AUTOSAR XML (schema 00046)
package /ComponentTypes
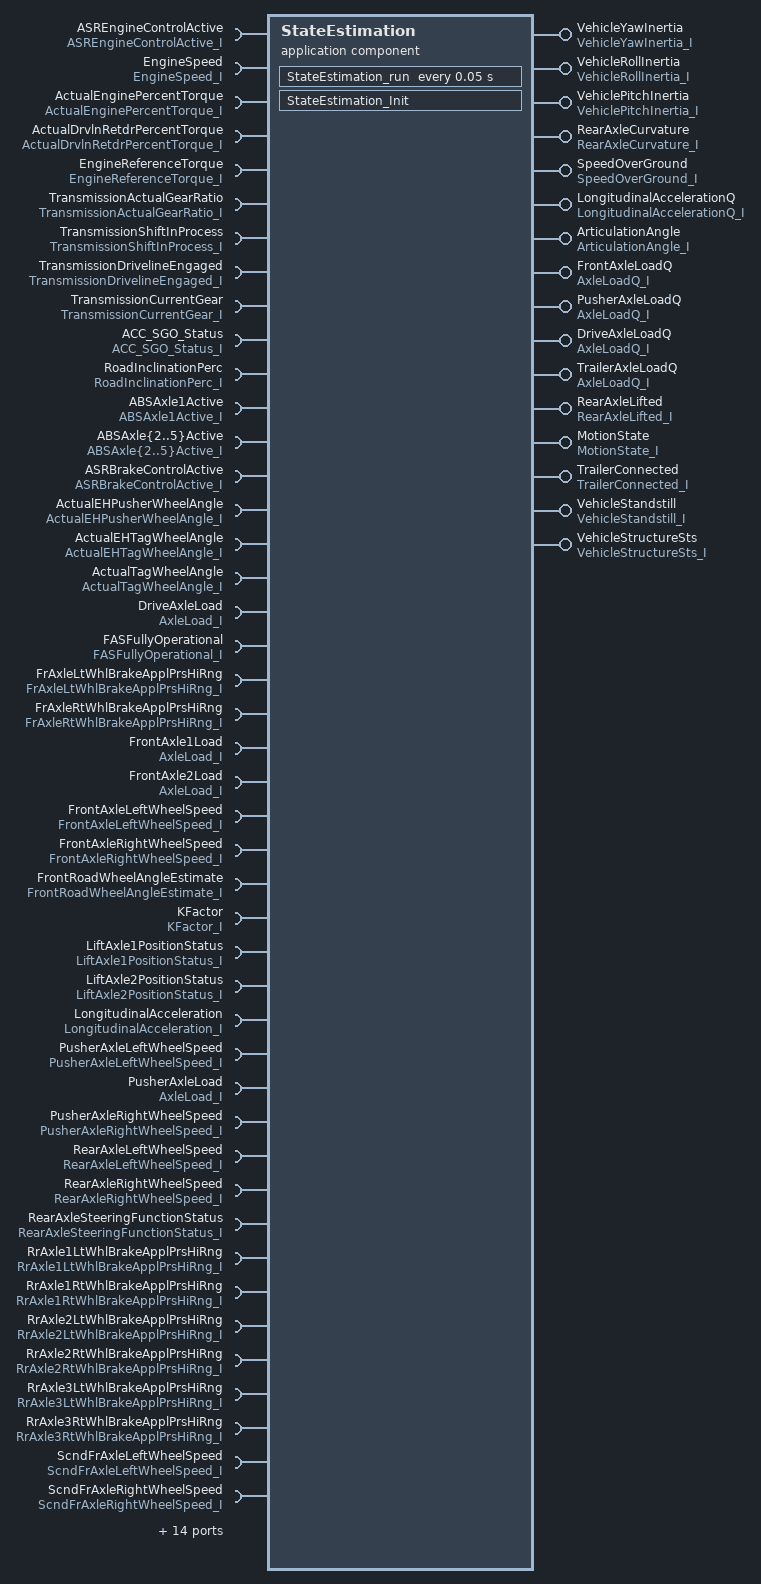
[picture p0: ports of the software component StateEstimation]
  application sw component type StateEstimation
    10 x require port:
      ASREngineControlActive: nonqueued-receiver-com-spec{data-element=ASREngineControlActive, alive-timeout=30, filter=data-filter-type=ALWAYS, init-value=constant-reference=C_ASREngineControlActive_IV}, required-interface=ASREngineControlActive_I
      EngineSpeed: nonqueued-receiver-com-spec{data-element=EngineSpeed, alive-timeout=30, init-value=constant-reference=C_EngineSpeed_IV}, required-interface=EngineSpeed_I
      ActualEnginePercentTorque: nonqueued-receiver-com-spec{data-element=ActualEnginePercentTorque, alive-timeout=30, init-value=constant-reference=C_ActualEnginePercentTorque_IV}, required-interface=ActualEnginePercentTorque_I
      ActualDrvlnRetdrPercentTorque: nonqueued-receiver-com-spec{data-element=ActualDrvlnRetdrPercentTorque, alive-timeout=30, init-value=constant-reference=C_ActualDrvlnRetdrPercentTorque_IV}, required-interface=ActualDrvlnRetdrPercentTorque_I
      EngineReferenceTorque: nonqueued-receiver-com-spec{data-element=EngineReferenceTorque, alive-timeout=30, filter=data-filter-type=ALWAYS, init-value=65535}, required-interface=EngineReferenceTorque_I
      TransmissionActualGearRatio: nonqueued-receiver-com-spec{data-element=TransmissionActualGearRatio, alive-timeout=30, init-value=constant-reference=C_TransmissionActualGearRatio_IV}, required-interface=TransmissionActualGearRatio_I
      TransmissionShiftInProcess: nonqueued-receiver-com-spec{data-element=TransmissionShiftInProcess, alive-timeout=30, init-value=constant-reference=C_TransmissionShiftInProcess_IV}, required-interface=TransmissionShiftInProcess_I
      TransmissionDrivelineEngaged: nonqueued-receiver-com-spec{data-element=TransmissionDrivelineEngaged, alive-timeout=30, init-value=constant-reference=C_TransmissionDrivelineEngaged_IV}, required-interface=TransmissionDrivelineEngaged_I
      TransmissionCurrentGear: nonqueued-receiver-com-spec{data-element=TransmissionCurrentGear, alive-timeout=30, init-value=constant-reference=C_TransmissionCurrentGear_IV}, required-interface=TransmissionCurrentGear_I
      ACC_SGO_Status: nonqueued-receiver-com-spec{data-element=ACC_SGO_Status, alive-timeout=30, init-value=constant-reference=C_ACC_SGO_Status_IV}, required-interface=ACC_SGO_Status_I
    15 x provide port:
      VehicleYawInertia: nonqueued-sender-com-spec{data-element=VehicleYawInertia, init-value=constant-reference=C_VehicleYawInertia_IV}, provided-interface=VehicleYawInertia_I
      VehicleRollInertia: nonqueued-sender-com-spec{data-element=VehicleRollInertia, init-value=constant-reference=C_VehicleRollInertia_IV}, provided-interface=VehicleRollInertia_I
      VehiclePitchInertia: nonqueued-sender-com-spec{data-element=VehiclePitchInertia, init-value=constant-reference=C_VehiclePitchInertia_IV}, provided-interface=VehiclePitchInertia_I
      RearAxleCurvature: nonqueued-sender-com-spec{data-element=RearAxleCurvature, init-value=constant-reference=C_RearAxleCurvature_IV}, provided-interface=RearAxleCurvature_I
      SpeedOverGround: nonqueued-sender-com-spec{data-element=SpeedOverGround, init-value=constant-reference=C_SpeedOverGround_IV}, provided-interface=SpeedOverGround_I
      LongitudinalAccelerationQ: nonqueued-sender-com-spec{data-element=LongitudinalAccelerationQ, init-value=constant-reference=C_LongAccelerationQ_IV}, provided-interface=LongitudinalAccelerationQ_I
      ArticulationAngle: nonqueued-sender-com-spec{data-element=ArticulationAngle, init-value=constant-reference=C_ArticulationAngle_IV}, provided-interface=ArticulationAngle_I
      FrontAxleLoadQ: nonqueued-sender-com-spec{data-element=AxleLoadQ_I, init-value=constant-reference=C_FrontAxleLoadQ_IV}, provided-interface=AxleLoadQ_I
      PusherAxleLoadQ: nonqueued-sender-com-spec{data-element=AxleLoadQ_I, init-value=constant-reference=C_PusherAxleLoadQ_IV}, provided-interface=AxleLoadQ_I
      DriveAxleLoadQ: nonqueued-sender-com-spec{data-element=AxleLoadQ_I, init-value=constant-reference=C_DriveAxleLoadQ_IV}, provided-interface=AxleLoadQ_I
      TrailerAxleLoadQ: nonqueued-sender-com-spec{data-element=AxleLoadQ_I, init-value=constant-reference=C_TrailerAxleLoadQ_IV}, provided-interface=AxleLoadQ_I
      RearAxleLifted: nonqueued-sender-com-spec{data-element=RearAxleLifted_I, init-value=constant-reference=C_RearAxleLifted_IV}, provided-interface=RearAxleLifted_I
      MotionState: nonqueued-sender-com-spec{data-element=MotionState_I, init-value=constant-reference=C_MotionState_IV}, provided-interface=MotionState_I
      TrailerConnected: nonqueued-sender-com-spec{data-element=TrailerConnected, init-value=constant-reference=C_TrailerConnected_IV}, provided-interface=TrailerConnected_I
      VehicleStandstill: nonqueued-sender-com-spec{data-element=VehicleStandstill, init-value=constant-reference=C_VehicleStandstill_IV}, provided-interface=VehicleStandstill_I
    45 x require port:
      RoadInclinationPerc: nonqueued-receiver-com-spec{data-element=RoadInclinationPerc, alive-timeout=30, init-value=0}, required-interface=RoadInclinationPerc_I
      ABSAxle1Active: nonqueued-receiver-com-spec{data-element=ABSAxle1Active, alive-timeout=30, init-value=constant-reference=C_ABSAxle1Active_IV}, required-interface=ABSAxle1Active_I
      ABSAxle{2..5}Active: nonqueued-receiver-com-spec{data-element=ABSAxle{2..5}Active, alive-timeout=30, filter=data-filter-type=ALWAYS, init-value=constant-reference=C_ABSAxle{2..5}Active_IV}, required-interface=ABSAxle{2..5}Active_I
      ASRBrakeControlActive: nonqueued-receiver-com-spec{data-element=ASRBrakeControlActive, alive-timeout=30, init-value=constant-reference=C_ASRBrakeControlActive_IV}, required-interface=ASRBrakeControlActive_I
      ActualEHPusherWheelAngle: nonqueued-receiver-com-spec{data-element=ActuaEHPusherWheelAngle, alive-timeout=30, filter=data-filter-type=ALWAYS, init-value=65535}, required-interface=ActualEHPusherWheelAngle_I
      ActualEHTagWheelAngle: nonqueued-receiver-com-spec{data-element=ActualEHTagWheelAngle, alive-timeout=30, filter=data-filter-type=ALWAYS, init-value=65535}, required-interface=ActualEHTagWheelAngle_I
      ActualTagWheelAngle: nonqueued-receiver-com-spec{data-element=ActualTagWheelAngle, alive-timeout=30, filter=data-filter-type=ALWAYS, init-value=constant-reference=C_ActualTagWheelAngle_IV}, required-interface=ActualTagWheelAngle_I
      DriveAxleLoad: nonqueued-receiver-com-spec{data-element=AxleLoad, alive-timeout=30, filter=data-filter-type=ALWAYS, init-value=constant-reference=C_DriveAxleLoad_IV}, required-interface=AxleLoad_I
      FASFullyOperational: nonqueued-receiver-com-spec{data-element=FASFullyOperational, alive-timeout=30, init-value=constant-reference=C_FASFullyOperational_IV}, required-interface=FASFullyOperational_I
      FrAxleLtWhlBrakeApplPrsHiRng: nonqueued-receiver-com-spec{data-element=FrAxleLtWhlBrakeApplPrsHiRng, alive-timeout=30, init-value=constant-reference=C_FrAxleLtWhlBrakeApplPrsHiRng_IV}, required-interface=FrAxleLtWhlBrakeApplPrsHiRng_I
      FrAxleRtWhlBrakeApplPrsHiRng: nonqueued-receiver-com-spec{data-element=FrAxleRtWhlBrakeApplPrsHiRng, alive-timeout=30, init-value=constant-reference=C_FrAxleRtWhlBrakeApplPrsHiRng_IV}, required-interface=FrAxleRtWhlBrakeApplPrsHiRng_I
      FrontAxle1Load: nonqueued-receiver-com-spec{data-element=AxleLoad, alive-timeout=30, filter=data-filter-type=ALWAYS, init-value=constant-reference=C_FrontAxle1Load_IV}, required-interface=AxleLoad_I
      FrontAxle2Load: nonqueued-receiver-com-spec{data-element=AxleLoad, alive-timeout=30, filter=data-filter-type=ALWAYS, init-value=constant-reference=C_FrontAxle2Load_IV}, required-interface=AxleLoad_I
      FrontAxleLeftWheelSpeed: nonqueued-receiver-com-spec{data-element=FrontAxleLeftWheelSpeed, alive-timeout=30, filter=data-filter-type=ALWAYS, init-value=constant-reference=C_FrontAxleLeftWheelSpeed_IV}, required-interface=FrontAxleLeftWheelSpeed_I
      FrontAxleRightWheelSpeed: nonqueued-receiver-com-spec{data-element=FrontAxleRightWheelSpeed, alive-timeout=30, filter=data-filter-type=ALWAYS, init-value=constant-reference=C_FrontAxleRightWheelSpeed_IV}, required-interface=FrontAxleRightWheelSpeed_I
      FrontRoadWheelAngleEstimate: nonqueued-receiver-com-spec{data-element=FrontRoadWheelAngleEstimate, alive-timeout=30, filter=data-filter-type=ALWAYS, init-value=constant-reference=C_FrontRoadWheelAngleEstimate_IV}, required-interface=FrontRoadWheelAngleEstimate_I
      KFactor: nonqueued-receiver-com-spec{data-element=KFactor, alive-timeout=30, init-value=constant-reference=C_kFactor_IV}, required-interface=KFactor_I
      LiftAxle1PositionStatus: nonqueued-receiver-com-spec{data-element=LiftAxle1PositionStatus, alive-timeout=30, filter=data-filter-type=ALWAYS, init-value=constant-reference=C_LiftAxle1PositionStatus_IV}, required-interface=LiftAxle1PositionStatus_I
      LiftAxle2PositionStatus: nonqueued-receiver-com-spec{data-element=LiftAxle2PositionStatus, alive-timeout=30, filter=data-filter-type=ALWAYS, init-value=constant-reference=C_LiftAxle2PositionStatus_IV}, required-interface=LiftAxle2PositionStatus_I
      LongitudinalAcceleration: nonqueued-receiver-com-spec{data-element=LongitudinalAcceleration, alive-timeout=30, filter=data-filter-type=ALWAYS, init-value=constant-reference=C_LongitudinalAcceleration_IV}, required-interface=LongitudinalAcceleration_I
      PusherAxleLeftWheelSpeed: nonqueued-receiver-com-spec{data-element=PusherAxleLeftWheelSpeed, alive-timeout=30, filter=data-filter-type=ALWAYS, init-value=constant-reference=C_RearAxleLeftWheelSpeed_IV}, required-interface=PusherAxleLeftWheelSpeed_I
      PusherAxleLoad: nonqueued-receiver-com-spec{data-element=AxleLoad, alive-timeout=30, filter=data-filter-type=ALWAYS, init-value=constant-reference=C_PusherAxleLoad_IV}, required-interface=AxleLoad_I
      PusherAxleRightWheelSpeed: nonqueued-receiver-com-spec{data-element=PusherAxleRightWheelSpeed, alive-timeout=30, filter=data-filter-type=ALWAYS, init-value=65535}, required-interface=PusherAxleRightWheelSpeed_I
      RearAxleLeftWheelSpeed: nonqueued-receiver-com-spec{data-element=RearAxleLeftWheelSpeed, alive-timeout=30, filter=data-filter-type=ALWAYS, init-value=constant-reference=C_RearAxleLeftWheelSpeed_IV}, required-interface=RearAxleLeftWheelSpeed_I
      RearAxleRightWheelSpeed: nonqueued-receiver-com-spec{data-element=RearAxleRightWheelSpeed, alive-timeout=30, filter=data-filter-type=ALWAYS, init-value=constant-reference=C_RearAxleRightWheelSpeed_IV}, required-interface=RearAxleRightWheelSpeed_I
      RearAxleSteeringFunctionStatus: nonqueued-receiver-com-spec{data-element=RearAxleSteeringFunctionStatus, alive-timeout=30, filter=data-filter-type=ALWAYS, init-value=constant-reference=C_RearAxleSteeringFunctionStatus_IV}, required-interface=RearAxleSteeringFunctionStatus_I
      RrAxle1LtWhlBrakeApplPrsHiRng: nonqueued-receiver-com-spec{data-element=RrAxle1LtWhlBrakeApplPrsHiRng, alive-timeout=30, init-value=constant-reference=C_RrAxle1LtWhlBrakeApplPrsHiRng_IV}, required-interface=RrAxle1LtWhlBrakeApplPrsHiRng_I
      RrAxle1RtWhlBrakeApplPrsHiRng: nonqueued-receiver-com-spec{data-element=RrAxle1RtWhlBrakeApplPrsHiRng, alive-timeout=30, init-value=constant-reference=C_RrAxle1RtWhlBrakeApplPrsHiRng_IV}, required-interface=RrAxle1RtWhlBrakeApplPrsHiRng_I
      RrAxle2LtWhlBrakeApplPrsHiRng: nonqueued-receiver-com-spec{data-element=RrAxle2LtWhlBrakeApplPrsHiRng, alive-timeout=30, init-value=constant-reference=C_RrAxle2LtWhlBrakeApplPrsHiRng_IV}, required-interface=RrAxle2LtWhlBrakeApplPrsHiRng_I
      RrAxle2RtWhlBrakeApplPrsHiRng: nonqueued-receiver-com-spec{data-element=RrAxle2RtWhlBrakeApplPrsHiRng, alive-timeout=30, init-value=constant-reference=C_RrAxle2RtWhlBrakeApplPrsHiRng_IV}, required-interface=RrAxle2RtWhlBrakeApplPrsHiRng_I
      RrAxle3LtWhlBrakeApplPrsHiRng: nonqueued-receiver-com-spec{data-element=RrAxle3LtWhlBrakeApplPrsHiRng, alive-timeout=30, init-value=constant-reference=C_RrAxle3LtWhlBrakeApplPrsHiRng_IV}, required-interface=RrAxle3LtWhlBrakeApplPrsHiRng_I
      RrAxle3RtWhlBrakeApplPrsHiRng: nonqueued-receiver-com-spec{data-element=RrAxle3RtWhlBrakeApplPrsHiRng, alive-timeout=30, init-value=constant-reference=C_RrAxle3RtWhlBrakeApplPrsHiRng_IV}, required-interface=RrAxle3RtWhlBrakeApplPrsHiRng_I
      ScndFrAxleLeftWheelSpeed: nonqueued-receiver-com-spec{data-element=ScndFrAxleLeftWheelSpeed, alive-timeout=30, filter=data-filter-type=ALWAYS, init-value=65535}, required-interface=ScndFrAxleLeftWheelSpeed_I
      ScndFrAxleRightWheelSpeed: nonqueued-receiver-com-spec{data-element=ScndFrAxleRightWheelSpeed, alive-timeout=30, filter=data-filter-type=ALWAYS, init-value=65535}, required-interface=ScndFrAxleRightWheelSpeed_I
      SecondaryDriveAxleLoad: nonqueued-receiver-com-spec{data-element=AxleLoad, alive-timeout=30, filter=data-filter-type=ALWAYS, init-value=constant-reference=C_SecondaryDriveAxleLoad_IV}, required-interface=AxleLoad_I
      SteeringWheelAngle: nonqueued-receiver-com-spec{data-element=SteeringWheelAngle, alive-timeout=30, filter=data-filter-type=ALWAYS, init-value=constant-reference=STEERING_WHEEL_ANGLE_INIT}, required-interface=SteeringWheelAngle_I
      TagAxleLeftWheelSpeed: nonqueued-receiver-com-spec{data-element=TagAxleLeftWheelSpeed, alive-timeout=30, filter=data-filter-type=ALWAYS, init-value=constant-reference=C_TagAxleLeftWheelSpeed_IV}, required-interface=TagAxleLeftWheelSpeed_I
      TagAxleLoad: nonqueued-receiver-com-spec{data-element=AxleLoad, alive-timeout=30, filter=data-filter-type=ALWAYS, init-value=constant-reference=C_TagAxleLoad_IV}, required-interface=AxleLoad_I
      TagAxleRightWheelSpeed: nonqueued-receiver-com-spec{data-element=TagAxleRightWheelSpeed, alive-timeout=30, filter=data-filter-type=ALWAYS, init-value=65535}, required-interface=TagAxleRightWheelSpeed_I
      TransmOutputShaftSpeedSigned: nonqueued-receiver-com-spec{data-element=TransmOutputShaftSpeedSigned, alive-timeout=30, init-value=constant-reference=C_TransmOutputShaftSpeedSigned_IV}, required-interface=TransmOutputShaftSpeedSigned_I
      XPRsystemstate: nonqueued-receiver-com-spec{data-element=XPRsystemstate, alive-timeout=30, filter=data-filter-type=ALWAYS, init-value=constant-reference=C_XPRsystemstate_IV}, required-interface=XPRsystemstate_I
      YawRate: nonqueued-receiver-com-spec{data-element=YawRate, alive-timeout=30, filter=data-filter-type=ALWAYS, init-value=65535}, required-interface=YawRate_I
    provide port VehicleStructureSts: nonqueued-sender-com-spec{data-element=VehicleStructureSts, init-value=constant-reference=C_VehicleStructureSts_IV}, provided-interface=VehicleStructureSts_I
    6 x require port:
      BswM_MSI_ESH_Mode: mode-switch-receiver-com-spec=BswM_MDGP_ESH_Mode, required-interface=BswM_MSI_ESH_Mode
      VehicleMode: nonqueued-receiver-com-spec{data-element=VehicleMode, alive-timeout=30, init-value=constant-reference=C_VehicleMode_IV}, required-interface=VehicleMode_I
      ScndRrDriveAxleLeftWheelSpeed: nonqueued-receiver-com-spec{data-element=ScndRrDriveAxleLeftWheelSpeed, alive-timeout=30, filter=data-filter-type=ALWAYS, init-value=constant-reference=C_ScndRrDriveAxleLeftWheelSpeed_IV}, required-interface=ScndRrDriveAxleLeftWheelSpeed_I
      ScndRrDriveAxleRightWheelSpeed: nonqueued-receiver-com-spec{data-element=ScndRrDriveAxleRightWheelSpeed, alive-timeout=30, init-value=constant-reference=C_ScndRrDriveAxleRightWheelSpeed_IV}, required-interface=ScndRrDriveAxleRightWheelSpeed_I
      FrontAxleSpeed: nonqueued-receiver-com-spec{data-element=FrontAxleSpeed, alive-timeout=30, init-value=constant-reference=C_FrontAxleSpeed_IV}, required-interface=FrontAxleSpeed_I
      ABSFullyOperational: nonqueued-receiver-com-spec{data-element=ABSFullyOperational, alive-timeout=30, init-value=constant-reference=C_ABSFullyOperational_IV}, required-interface=ABSFullyOperational_I
    behavior StateEstimation_InternalBehavior
      timing event TMT_StateEstimation_run: start-on-event=StateEstimation_run, period=0.05
      swc mode switch event MST_StateEstimation_Init_0: start-on-event=StateEstimation_Init, activation=ON-ENTRY, mode=BswM_MSI_ESH_Mode.BswM_MDGP_ESH_Mode.RUN
      runnable StateEstimation_Init
      runnable StateEstimation_run
        data-receive-point-by-arguments:
          60 x access:
            REC_ABSAxle{1..5}Active_ABSAxle{1..5}Active: accessed-variable=ABSAxle{1..5}Active.ABSAxle{1..5}Active
            REC_ACC_SGO_Status_ACC_SGO_Status: accessed-variable=ACC_SGO_Status.ACC_SGO_Status
            REC_ASRBrakeControlActive_ASRBrakeControlActive: accessed-variable=ASRBrakeControlActive.ASRBrakeControlActive
            REC_ASREngineControlActive_ASREngineControlActive: accessed-variable=ASREngineControlActive.ASREngineControlActive
            REC_ActualDrvlnRetdrPercentTorque_ActualDrvlnRetdrPercentTorque: accessed-variable=ActualDrvlnRetdrPercentTorque.ActualDrvlnRetdrPercentTorque
            REC_ActualEHPusherWheelAngle_ActuaEHPusherWheelAngle: accessed-variable=ActualEHPusherWheelAngle.ActuaEHPusherWheelAngle
            REC_ActualEHTagWheelAngle_ActualEHTagWheelAngle: accessed-variable=ActualEHTagWheelAngle.ActualEHTagWheelAngle
            REC_ActualEnginePercentTorque_ActualEnginePercentTorque: accessed-variable=ActualEnginePercentTorque.ActualEnginePercentTorque
            REC_ActualTagWheelAngle_ActualTagWheelAngle: accessed-variable=ActualTagWheelAngle.ActualTagWheelAngle
            REC_DriveAxleLoad_AxleLoad: accessed-variable=DriveAxleLoad.AxleLoad
            REC_EngineReferenceTorque_EngineReferenceTorque: accessed-variable=EngineReferenceTorque.EngineReferenceTorque
            REC_EngineSpeed_EngineSpeed: accessed-variable=EngineSpeed.EngineSpeed
            REC_FASFullyOperational_FASFullyOperational: accessed-variable=FASFullyOperational.FASFullyOperational
            REC_FrAxleLtWhlBrakeApplPrsHiRng_FrAxleLtWhlBrakeApplPrsHiRng: accessed-variable=FrAxleLtWhlBrakeApplPrsHiRng.FrAxleLtWhlBrakeApplPrsHiRng
            REC_FrAxleRtWhlBrakeApplPrsHiRng_FrAxleRtWhlBrakeApplPrsHiRng: accessed-variable=FrAxleRtWhlBrakeApplPrsHiRng.FrAxleRtWhlBrakeApplPrsHiRng
            REC_FrontAxle1Load_AxleLoad: accessed-variable=FrontAxle1Load.AxleLoad
            REC_FrontAxle2Load_AxleLoad: accessed-variable=FrontAxle2Load.AxleLoad
            REC_FrontAxleLeftWheelSpeed_FrontAxleLeftWheelSpeed: accessed-variable=FrontAxleLeftWheelSpeed.FrontAxleLeftWheelSpeed
            REC_FrontAxleRightWheelSpeed_FrontAxleRightWheelSpeed: accessed-variable=FrontAxleRightWheelSpeed.FrontAxleRightWheelSpeed
            REC_FrontRoadWheelAngleEstimate_FrontRoadWheelAngleEstimate: accessed-variable=FrontRoadWheelAngleEstimate.FrontRoadWheelAngleEstimate
            REC_KFactor_KFactor: accessed-variable=KFactor.KFactor
            REC_LiftAxle1PositionStatus_LiftAxle1PositionStatus: accessed-variable=LiftAxle1PositionStatus.LiftAxle1PositionStatus
            REC_LiftAxle2PositionStatus_LiftAxle2PositionStatus: accessed-variable=LiftAxle2PositionStatus.LiftAxle2PositionStatus
            REC_LongitudinalAcceleration_LongitudinalAcceleration: accessed-variable=LongitudinalAcceleration.LongitudinalAcceleration
            REC_PusherAxleLeftWheelSpeed_PusherAxleLeftWheelSpeed: accessed-variable=PusherAxleLeftWheelSpeed.PusherAxleLeftWheelSpeed
            REC_PusherAxleLoad_AxleLoad: accessed-variable=PusherAxleLoad.AxleLoad
            REC_PusherAxleRightWheelSpeed_PusherAxleRightWheelSpeed: accessed-variable=PusherAxleRightWheelSpeed.PusherAxleRightWheelSpeed
            REC_RearAxleLeftWheelSpeed_RearAxleLeftWheelSpeed: accessed-variable=RearAxleLeftWheelSpeed.RearAxleLeftWheelSpeed
            REC_RearAxleRightWheelSpeed_RearAxleRightWheelSpeed: accessed-variable=RearAxleRightWheelSpeed.RearAxleRightWheelSpeed
            REC_RearAxleSteeringFunctionStatus_RearAxleSteeringFunctionStatus: accessed-variable=RearAxleSteeringFunctionStatus.RearAxleSteeringFunctionStatus
            REC_RoadInclinationPerc_RoadInclinationPerc: accessed-variable=RoadInclinationPerc.RoadInclinationPerc
            REC_RrAxle1LtWhlBrakeApplPrsHiRng_RrAxle1LtWhlBrakeApplPrsHiRng: accessed-variable=RrAxle1LtWhlBrakeApplPrsHiRng.RrAxle1LtWhlBrakeApplPrsHiRng
            REC_RrAxle1RtWhlBrakeApplPrsHiRng_RrAxle1RtWhlBrakeApplPrsHiRng: accessed-variable=RrAxle1RtWhlBrakeApplPrsHiRng.RrAxle1RtWhlBrakeApplPrsHiRng
            REC_RrAxle2LtWhlBrakeApplPrsHiRng_RrAxle2LtWhlBrakeApplPrsHiRng: accessed-variable=RrAxle2LtWhlBrakeApplPrsHiRng.RrAxle2LtWhlBrakeApplPrsHiRng
            REC_RrAxle2RtWhlBrakeApplPrsHiRng_RrAxle2RtWhlBrakeApplPrsHiRng: accessed-variable=RrAxle2RtWhlBrakeApplPrsHiRng.RrAxle2RtWhlBrakeApplPrsHiRng
            REC_RrAxle3LtWhlBrakeApplPrsHiRng_RrAxle3LtWhlBrakeApplPrsHiRng: accessed-variable=RrAxle3LtWhlBrakeApplPrsHiRng.RrAxle3LtWhlBrakeApplPrsHiRng
            REC_RrAxle3RtWhlBrakeApplPrsHiRng_RrAxle3RtWhlBrakeApplPrsHiRng: accessed-variable=RrAxle3RtWhlBrakeApplPrsHiRng.RrAxle3RtWhlBrakeApplPrsHiRng
            REC_ScndFrAxleLeftWheelSpeed_ScndFrAxleLeftWheelSpeed: accessed-variable=ScndFrAxleLeftWheelSpeed.ScndFrAxleLeftWheelSpeed
            REC_ScndFrAxleRightWheelSpeed_ScndFrAxleRightWheelSpeed: accessed-variable=ScndFrAxleRightWheelSpeed.ScndFrAxleRightWheelSpeed
            REC_SecondaryDriveAxleLoad_AxleLoad: accessed-variable=SecondaryDriveAxleLoad.AxleLoad
            REC_SteeringWheelAngle_SteeringWheelAngle: accessed-variable=SteeringWheelAngle.SteeringWheelAngle
            REC_TagAxleLeftWheelSpeed_TagAxleLeftWheelSpeed: accessed-variable=TagAxleLeftWheelSpeed.TagAxleLeftWheelSpeed
            REC_TagAxleLoad_AxleLoad: accessed-variable=TagAxleLoad.AxleLoad
            REC_TagAxleRightWheelSpeed_TagAxleRightWheelSpeed: accessed-variable=TagAxleRightWheelSpeed.TagAxleRightWheelSpeed
            REC_TransmOutputShaftSpeedSigned_TransmOutputShaftSpeedSigned: accessed-variable=TransmOutputShaftSpeedSigned.TransmOutputShaftSpeedSigned
            REC_TransmissionActualGearRatio_TransmissionActualGearRatio: accessed-variable=TransmissionActualGearRatio.TransmissionActualGearRatio
            REC_TransmissionCurrentGear_TransmissionCurrentGear: accessed-variable=TransmissionCurrentGear.TransmissionCurrentGear
            REC_TransmissionDrivelineEngaged_TransmissionDrivelineEngaged: accessed-variable=TransmissionDrivelineEngaged.TransmissionDrivelineEngaged
            REC_TransmissionShiftInProcess_TransmissionShiftInProcess: accessed-variable=TransmissionShiftInProcess.TransmissionShiftInProcess
            REC_XPRsystemstate_XPRsystemstate: accessed-variable=XPRsystemstate.XPRsystemstate
            REC_YawRate_YawRate: accessed-variable=YawRate.YawRate
            REC_VehicleMode_VehicleMode: accessed-variable=VehicleMode.VehicleMode
            REC_FrontAxleSpeed_FrontAxleSpeed: accessed-variable=FrontAxleSpeed.FrontAxleSpeed
            REC_ScndRrDriveAxleLeftWheelSpeed_ScndRrDriveAxleLeftWheelSpeed: accessed-variable=ScndRrDriveAxleLeftWheelSpeed.ScndRrDriveAxleLeftWheelSpeed
            REC_ScndRrDriveAxleRightWheelSpeed_ScndRrDriveAxleRightWheelSpeed: accessed-variable=ScndRrDriveAxleRightWheelSpeed.ScndRrDriveAxleRightWheelSpeed
            REC_ABSFullyOperational_ABSFullyOperational: accessed-variable=ABSFullyOperational.ABSFullyOperational
        data-send-points:
          16 x access:
            SEND_ArticulationAngle_ArticulationAngle: accessed-variable=ArticulationAngle.ArticulationAngle
            SEND_DriveAxleLoadQ_AxleLoadQ_I: accessed-variable=DriveAxleLoadQ.AxleLoadQ_I
            SEND_FrontAxleLoadQ_AxleLoadQ_I: accessed-variable=FrontAxleLoadQ.AxleLoadQ_I
            SEND_LongitudinalAccelerationQ_LongitudinalAccelerationQ: accessed-variable=LongitudinalAccelerationQ.LongitudinalAccelerationQ
            SEND_MotionState_MotionState_I: accessed-variable=MotionState.MotionState_I
            SEND_PusherAxleLoadQ_AxleLoadQ_I: accessed-variable=PusherAxleLoadQ.AxleLoadQ_I
            SEND_RearAxleCurvature_RearAxleCurvature: accessed-variable=RearAxleCurvature.RearAxleCurvature
            SEND_RearAxleLifted_RearAxleLifted_I: accessed-variable=RearAxleLifted.RearAxleLifted_I
            SEND_SpeedOverGround_SpeedOverGround: accessed-variable=SpeedOverGround.SpeedOverGround
            SEND_TrailerAxleLoadQ_AxleLoadQ_I: accessed-variable=TrailerAxleLoadQ.AxleLoadQ_I
            SEND_TrailerConnected_TrailerConnected: accessed-variable=TrailerConnected.TrailerConnected
            SEND_VehiclePitchInertia_VehiclePitchInertia: accessed-variable=VehiclePitchInertia.VehiclePitchInertia
            SEND_VehicleRollInertia_VehicleRollInertia: accessed-variable=VehicleRollInertia.VehicleRollInertia
            SEND_VehicleStandstill_VehicleStandstill: accessed-variable=VehicleStandstill.VehicleStandstill
            SEND_VehicleStructureSts_VehicleStructureSts: accessed-variable=VehicleStructureSts.VehicleStructureSts
            SEND_VehicleYawInertia_VehicleYawInertia: accessed-variable=VehicleYawInertia.VehicleYawInertia
  swc implementation StateEstimation_Implementation: behavior=StateEstimation_InternalBehavior
